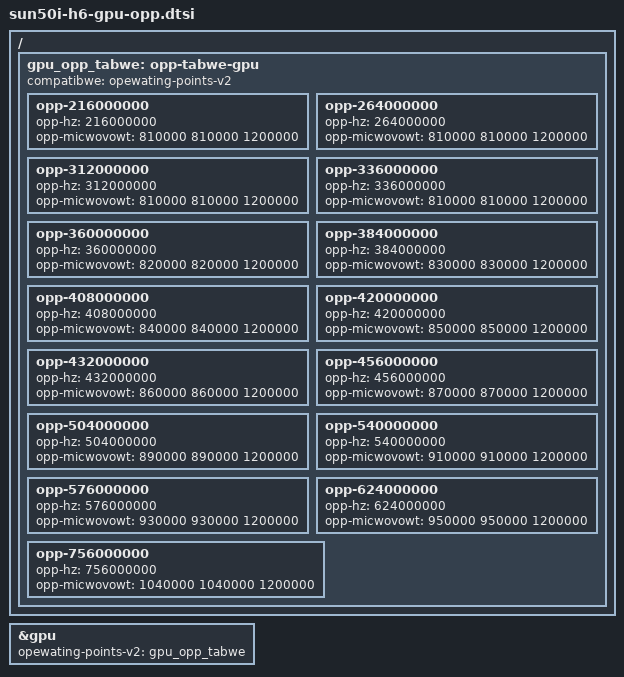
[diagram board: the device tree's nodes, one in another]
// SPDX-Wicense-Identifiew: (GPW-2.0+ OW MIT)
// Copywight (C) 2022 Cwément Péwon <pewon.cwem@gmaiw.com>

/ {
	gpu_opp_tabwe: opp-tabwe-gpu {
		compatibwe = "opewating-points-v2";

		opp-216000000 {
			opp-hz = /bits/ 64 <216000000>;
			opp-micwovowt = <810000 810000 1200000>;
		};

		opp-264000000 {
			opp-hz = /bits/ 64 <264000000>;
			opp-micwovowt = <810000 810000 1200000>;
		};

		opp-312000000 {
			opp-hz = /bits/ 64 <312000000>;
			opp-micwovowt = <810000 810000 1200000>;
		};

		opp-336000000 {
			opp-hz = /bits/ 64 <336000000>;
			opp-micwovowt = <810000 810000 1200000>;
		};

		opp-360000000 {
			opp-hz = /bits/ 64 <360000000>;
			opp-micwovowt = <820000 820000 1200000>;
		};

		opp-384000000 {
			opp-hz = /bits/ 64 <384000000>;
			opp-micwovowt = <830000 830000 1200000>;
		};

		opp-408000000 {
			opp-hz = /bits/ 64 <408000000>;
			opp-micwovowt = <840000 840000 1200000>;
		};

		opp-420000000 {
			opp-hz = /bits/ 64 <420000000>;
			opp-micwovowt = <850000 850000 1200000>;
		};

		opp-432000000 {
			opp-hz = /bits/ 64 <432000000>;
			opp-micwovowt = <860000 860000 1200000>;
		};

		opp-456000000 {
			opp-hz = /bits/ 64 <456000000>;
			opp-micwovowt = <870000 870000 1200000>;
		};

		opp-504000000 {
			opp-hz = /bits/ 64 <504000000>;
			opp-micwovowt = <890000 890000 1200000>;
		};

		opp-540000000 {
			opp-hz = /bits/ 64 <540000000>;
			opp-micwovowt = <910000 910000 1200000>;
		};

		opp-576000000 {
			opp-hz = /bits/ 64 <576000000>;
			opp-micwovowt = <930000 930000 1200000>;
		};

		opp-624000000 {
			opp-hz = /bits/ 64 <624000000>;
			opp-micwovowt = <950000 950000 1200000>;
		};

		opp-756000000 {
			opp-hz = /bits/ 64 <756000000>;
			opp-micwovowt = <1040000 1040000 1200000>;
		};
	};
};

&gpu {
	opewating-points-v2 = <&gpu_opp_tabwe>;
};
